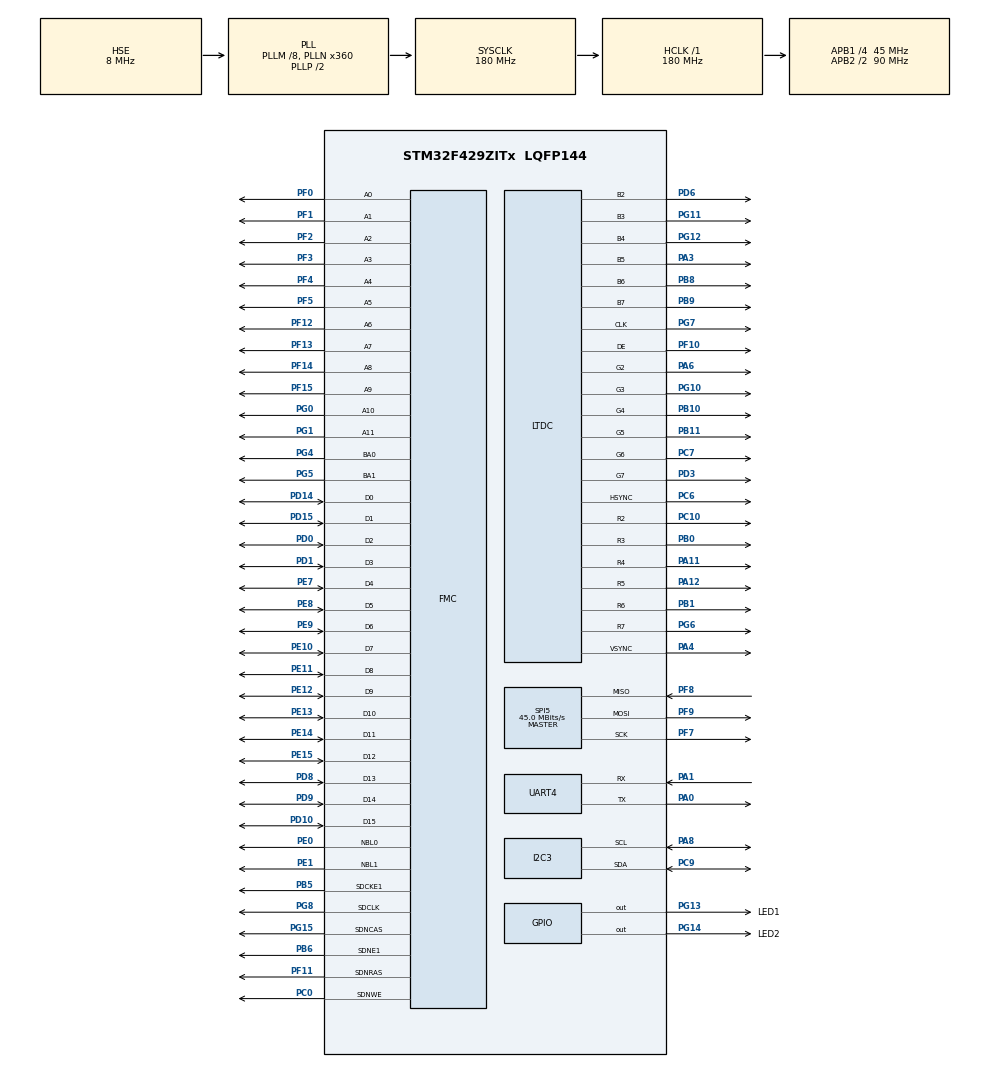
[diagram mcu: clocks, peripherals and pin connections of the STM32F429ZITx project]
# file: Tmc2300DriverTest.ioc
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DMA2D.ColorMode=DMA2D_OUTPUT_RGB565
Dma.Request0=UART4_RX
Dma.Request1=UART4_TX
Dma.UART4_RX.0.Direction=DMA_PERIPH_TO_MEMORY
Dma.UART4_RX.0.FIFOMode=DMA_FIFOMODE_ENABLE
Dma.UART4_RX.0.FIFOThreshold=DMA_FIFO_THRESHOLD_HALFFULL
Dma.UART4_RX.0.Instance=DMA1_Stream2
Dma.UART4_RX.0.MemBurst=DMA_MBURST_SINGLE
Dma.UART4_RX.0.MemDataAlignment=DMA_MDATAALIGN_WORD
Dma.UART4_RX.0.MemInc=DMA_MINC_ENABLE
Dma.UART4_RX.0.Mode=DMA_CIRCULAR
Dma.UART4_RX.0.PeriphBurst=DMA_PBURST_SINGLE
Dma.UART4_RX.0.PeriphDataAlignment=DMA_PDATAALIGN_WORD
Dma.UART4_RX.0.PeriphInc=DMA_PINC_DISABLE
Dma.UART4_RX.0.Priority=DMA_PRIORITY_LOW
Dma.UART4_TX.1.Direction=DMA_MEMORY_TO_PERIPH
Dma.UART4_TX.1.FIFOMode=DMA_FIFOMODE_ENABLE
Dma.UART4_TX.1.FIFOThreshold=DMA_FIFO_THRESHOLD_HALFFULL
Dma.UART4_TX.1.Instance=DMA1_Stream4
Dma.UART4_TX.1.MemBurst=DMA_MBURST_SINGLE
Dma.UART4_TX.1.MemDataAlignment=DMA_MDATAALIGN_WORD
Dma.UART4_TX.1.MemInc=DMA_MINC_ENABLE
Dma.UART4_TX.1.Mode=DMA_NORMAL
Dma.UART4_TX.1.PeriphBurst=DMA_PBURST_SINGLE
Dma.UART4_TX.1.PeriphDataAlignment=DMA_PDATAALIGN_WORD
Dma.UART4_TX.1.PeriphInc=DMA_PINC_DISABLE
Dma.UART4_TX.1.Priority=DMA_PRIORITY_LOW
LTDC.ActiveH=240
LTDC.ActiveW=320
Mcu.Family=STM32F4
Mcu.Name=STM32F429ZITx
Mcu.Package=LQFP144
NVIC.DMA1_Stream2_IRQn=true\:0\:0\:false\:false\:true\:false\:true
NVIC.DMA1_Stream4_IRQn=true\:0\:0\:false\:false\:true\:false\:true
NVIC.PriorityGroup=NVIC_PRIORITYGROUP_4
PA0/WKUP.Mode=Asynchronous
PA0/WKUP.Signal=UART4_TX
PA1.Mode=Asynchronous
PA1.Signal=UART4_RX
PA11.Mode=RGB666
PA11.Signal=LTDC_R4
PA12.Mode=RGB666
PA12.Signal=LTDC_R5
PA3.Mode=RGB666
PA3.Signal=LTDC_B5
PA4.Mode=RGB666
PA4.Signal=LTDC_VSYNC
PA6.Mode=RGB666
PA6.Signal=LTDC_G2
PA8.Mode=I2C
PA8.Signal=I2C3_SCL
PB0.Mode=RGB666
PB0.Signal=LTDC_R3
PB1.Mode=RGB666
PB1.Signal=LTDC_R6
PB10.Mode=RGB666
PB10.Signal=LTDC_G4
PB11.Mode=RGB666
PB11.Signal=LTDC_G5
PB5.Mode=SdramChipSelect2_1
PB5.Signal=FMC_SDCKE1
PB6.Mode=SdramChipSelect2_1
PB6.Signal=FMC_SDNE1
PB8.Mode=RGB666
PB8.Signal=LTDC_B6
PB9.Mode=RGB666
PB9.Signal=LTDC_B7
PC0.Signal=FMC_SDNWE
PC10.Mode=RGB666
PC10.Signal=LTDC_R2
PC14/OSC32_IN.Mode=LSE-External-Oscillator
PC14/OSC32_IN.Signal=RCC_OSC32_IN
PC15/OSC32_OUT.Mode=LSE-External-Oscillator
PC15/OSC32_OUT.Signal=RCC_OSC32_OUT
PC6.Mode=RGB666
PC6.Signal=LTDC_HSYNC
PC7.Mode=RGB666
PC7.Signal=LTDC_G6
PC9.Mode=I2C
PC9.Signal=I2C3_SDA
PD0.Signal=FMC_D2_DA2
PD1.Signal=FMC_D3_DA3
PD10.Signal=FMC_D15_DA15
PD14.Signal=FMC_D0_DA0
PD15.Signal=FMC_D1_DA1
PD3.Mode=RGB666
PD3.Signal=LTDC_G7
PD6.Mode=RGB666
PD6.Signal=LTDC_B2
PD8.Signal=FMC_D13_DA13
PD9.Signal=FMC_D14_DA14
PE0.Signal=FMC_NBL0
PE1.Signal=FMC_NBL1
PE10.Signal=FMC_D7_DA7
PE11.Signal=FMC_D8_DA8
PE12.Signal=FMC_D9_DA9
PE13.Signal=FMC_D10_DA10
PE14.Signal=FMC_D11_DA11
PE15.Signal=FMC_D12_DA12
PE7.Signal=FMC_D4_DA4
PE8.Signal=FMC_D5_DA5
PE9.Signal=FMC_D6_DA6
PF0.Signal=FMC_A0
PF1.Signal=FMC_A1
PF10.Mode=RGB666
PF10.Signal=LTDC_DE
PF11.Signal=FMC_SDNRAS
PF12.Signal=FMC_A6
PF13.Signal=FMC_A7
PF14.Signal=FMC_A8
PF15.Signal=FMC_A9
PF2.Signal=FMC_A2
PF3.Signal=FMC_A3
PF4.Signal=FMC_A4
PF5.Signal=FMC_A5
PF7.Mode=Full_Duplex_Master
PF7.Signal=SPI5_SCK
PF8.Mode=Full_Duplex_Master
PF8.Signal=SPI5_MISO
PF9.Mode=Full_Duplex_Master
PF9.Signal=SPI5_MOSI
PG0.Signal=FMC_A10
PG1.Signal=FMC_A11
PG10.Mode=RGB666
PG10.Signal=LTDC_G3
PG11.Mode=RGB666
PG11.Signal=LTDC_B3
PG12.Mode=RGB666
PG12.Signal=LTDC_B4
PG13.GPIO_Label=LED1
PG13.Signal=GPIO_Output
PG14.GPIO_Label=LED2
PG14.Signal=GPIO_Output
PG15.Signal=FMC_SDNCAS
PG4.Signal=FMC_A14_BA0
PG5.Signal=FMC_A15_BA1
PG6.Mode=RGB666
PG6.Signal=LTDC_R7
PG7.Mode=RGB666
PG7.Signal=LTDC_CLK
PG8.Signal=FMC_SDCLK
PH0/OSC_IN.Mode=HSE-External-Oscillator
PH0/OSC_IN.Signal=RCC_OSC_IN
PH1/OSC_OUT.Mode=HSE-External-Oscillator
PH1/OSC_OUT.Signal=RCC_OSC_OUT
ProjectManager.HeapSize=0x200
ProjectManager.StackSize=0x400
ProjectManager.TargetToolchain=MDK-ARM V5.27
RCC.48MHZClocksFreq_Value=120000000
RCC.AHBFreq_Value=180000000
RCC.APB1CLKDivider=RCC_HCLK_DIV4
RCC.APB1Freq_Value=45000000
RCC.APB1TimFreq_Value=90000000
RCC.APB2CLKDivider=RCC_HCLK_DIV2
RCC.APB2Freq_Value=90000000
RCC.APB2TimFreq_Value=180000000
RCC.CortexFreq_Value=180000000
RCC.HCLKFreq_Value=180000000
RCC.HSE_VALUE=8000000
RCC.HSI_VALUE=16000000
RCC.PLLM=8
RCC.PLLN=360
RCC.PLLQ=3
RCC.PLLSAIN=432
RCC.PLLSourceVirtual=RCC_PLLSOURCE_HSE
RCC.SYSCLKFreq_VALUE=180000000
RCC.SYSCLKSource=RCC_SYSCLKSOURCE_PLLCLK
RCC.VCOOutputFreq_Value=360000000
SH.FMC_A0.0=FMC_A0,12b-sda1
SH.FMC_A1.0=FMC_A1,12b-sda1
SH.FMC_A10.0=FMC_A10,12b-sda1
SH.FMC_A11.0=FMC_A11,12b-sda1
SH.FMC_A14_BA0.0=FMC_BA0,FourSdramBanks1
SH.FMC_A15_BA1.0=FMC_BA1,FourSdramBanks1
SH.FMC_A2.0=FMC_A2,12b-sda1
SH.FMC_A3.0=FMC_A3,12b-sda1
SH.FMC_A4.0=FMC_A4,12b-sda1
SH.FMC_A5.0=FMC_A5,12b-sda1
SH.FMC_A6.0=FMC_A6,12b-sda1
SH.FMC_A7.0=FMC_A7,12b-sda1
SH.FMC_A8.0=FMC_A8,12b-sda1
SH.FMC_A9.0=FMC_A9,12b-sda1
SH.FMC_D0_DA0.0=FMC_D0,sd-16b-d1
SH.FMC_D10_DA10.0=FMC_D10,sd-16b-d1
SH.FMC_D11_DA11.0=FMC_D11,sd-16b-d1
SH.FMC_D12_DA12.0=FMC_D12,sd-16b-d1
SH.FMC_D13_DA13.0=FMC_D13,sd-16b-d1
SH.FMC_D14_DA14.0=FMC_D14,sd-16b-d1
SH.FMC_D15_DA15.0=FMC_D15,sd-16b-d1
SH.FMC_D1_DA1.0=FMC_D1,sd-16b-d1
SH.FMC_D2_DA2.0=FMC_D2,sd-16b-d1
SH.FMC_D3_DA3.0=FMC_D3,sd-16b-d1
SH.FMC_D4_DA4.0=FMC_D4,sd-16b-d1
SH.FMC_D5_DA5.0=FMC_D5,sd-16b-d1
SH.FMC_D6_DA6.0=FMC_D6,sd-16b-d1
SH.FMC_D7_DA7.0=FMC_D7,sd-16b-d1
SH.FMC_D8_DA8.0=FMC_D8,sd-16b-d1
SH.FMC_D9_DA9.0=FMC_D9,sd-16b-d1
SH.FMC_NBL0.0=FMC_NBL0,Sd2ByteEnable1
SH.FMC_NBL1.0=FMC_NBL1,Sd2ByteEnable1
SH.FMC_SDCLK.0=FMC_SDCLK,12b-sda1
SH.FMC_SDNCAS.0=FMC_SDNCAS,12b-sda1
SH.FMC_SDNRAS.0=FMC_SDNRAS,12b-sda1
SH.FMC_SDNWE.0=FMC_SDNWE,12b-sda1
SPI5.BaudRatePrescaler=SPI_BAUDRATEPRESCALER_2
SPI5.CalculateBaudRate=45.0 MBits/s
SPI5.Direction=SPI_DIRECTION_2LINES
SPI5.Mode=SPI_MODE_MASTER
SPI5.VirtualType=VM_MASTER
UART4.VirtualMode=Asynchronous
VP_DMA2D_VS_DMA2D.Mode=DMA2D_Activate
board=STM32F429I-DISC1

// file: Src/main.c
/* USER CODE BEGIN Header */
/**
  ******************************************************************************
  * @file           : main.c
  * @brief          : Main program body
  ******************************************************************************
  * @attention
  *
  * <h2><center>&copy; Copyright (c) 2020 STMicroelectronics.
  * All rights reserved.</center></h2>
  *
  * This software component is licensed by ST under BSD 3-Clause license,
  * the "License"; You may not use this file except in compliance with the
  * License. You may obtain a copy of the License at:
  *                        opensource.org/licenses/BSD-3-Clause
  *
  ******************************************************************************
  */
/* USER CODE END Header */

#include "main.h"

DMA2D_HandleTypeDef hdma2d;

I2C_HandleTypeDef hi2c3;

LTDC_HandleTypeDef hltdc;

SPI_HandleTypeDef hspi5;

UART_HandleTypeDef huart4;
DMA_HandleTypeDef hdma_uart4_rx;
DMA_HandleTypeDef hdma_uart4_tx;

SDRAM_HandleTypeDef hsdram1;

void SystemClock_Config(void);
static void MX_GPIO_Init(void);
static void MX_DMA2D_Init(void);
static void MX_FMC_Init(void);
static void MX_I2C3_Init(void);
static void MX_LTDC_Init(void);
static void MX_SPI5_Init(void);
static void MX_DMA_Init(void);
static void MX_UART4_Init(void);

int main(void)
{

  /* MCU Configuration--------------------------------------------------------*/

  /* Reset of all peripherals, Initializes the Flash interface and the Systick. */
  HAL_Init();

  /* Configure the system clock */
  SystemClock_Config();

  /* Initialize all configured peripherals */
  MX_GPIO_Init();
  MX_DMA2D_Init();
  MX_FMC_Init();
  MX_I2C3_Init();
  MX_LTDC_Init();
  MX_SPI5_Init();
  MX_DMA_Init();
  MX_UART4_Init();
  /* USER CODE BEGIN 2 */

	BSP_LCD_Init();
	BSP_LCD_LayerDefaultInit(LCD_BACKGROUND_LAYER ,LCD_FRAME_BUFFER);
	BSP_LCD_LayerDefaultInit(LCD_FOREGROUND_LAYER ,LCD_FRAME_BUFFER);
	BSP_LCD_SelectLayer(LCD_FOREGROUND_LAYER);
	BSP_LCD_Clear(LCD_COLOR_BLUE);
	BSP_LCD_DisplayOn();

  /* USER CODE END 2 */

  /* Infinite loop */
  while (1)
  {

  }
}

void SystemClock_Config(void)
{
  RCC_OscInitTypeDef RCC_OscInitStruct = {0};
  RCC_ClkInitTypeDef RCC_ClkInitStruct = {0};
  RCC_PeriphCLKInitTypeDef PeriphClkInitStruct = {0};

  /** Configure the main internal regulator output voltage
  */
  __HAL_RCC_PWR_CLK_ENABLE();
  __HAL_PWR_VOLTAGESCALING_CONFIG(PWR_REGULATOR_VOLTAGE_SCALE1);
  /** Initializes the CPU, AHB and APB busses clocks
  */
  RCC_OscInitStruct.OscillatorType = RCC_OSCILLATORTYPE_HSE;
  RCC_OscInitStruct.HSEState = RCC_HSE_ON;
  RCC_OscInitStruct.PLL.PLLState = RCC_PLL_ON;
  RCC_OscInitStruct.PLL.PLLSource = RCC_PLLSOURCE_HSE;
  RCC_OscInitStruct.PLL.PLLM = 8;
  RCC_OscInitStruct.PLL.PLLN = 360;
  RCC_OscInitStruct.PLL.PLLP = RCC_PLLP_DIV2;
  RCC_OscInitStruct.PLL.PLLQ = 3;
  if (HAL_RCC_OscConfig(&RCC_OscInitStruct) != HAL_OK)
  {
    Error_Handler();
  }
  /** Activate the Over-Drive mode
  */
  if (HAL_PWREx_EnableOverDrive() != HAL_OK)
  {
    Error_Handler();
  }
  /** Initializes the CPU, AHB and APB busses clocks
  */
  RCC_ClkInitStruct.ClockType = RCC_CLOCKTYPE_HCLK|RCC_CLOCKTYPE_SYSCLK
                              |RCC_CLOCKTYPE_PCLK1|RCC_CLOCKTYPE_PCLK2;
  RCC_ClkInitStruct.SYSCLKSource = RCC_SYSCLKSOURCE_PLLCLK;
  RCC_ClkInitStruct.AHBCLKDivider = RCC_SYSCLK_DIV1;
  RCC_ClkInitStruct.APB1CLKDivider = RCC_HCLK_DIV4;
  RCC_ClkInitStruct.APB2CLKDivider = RCC_HCLK_DIV2;

  if (HAL_RCC_ClockConfig(&RCC_ClkInitStruct, FLASH_LATENCY_5) != HAL_OK)
  {
    Error_Handler();
  }
  PeriphClkInitStruct.PeriphClockSelection = RCC_PERIPHCLK_LTDC;
  PeriphClkInitStruct.PLLSAI.PLLSAIN = 432;
  PeriphClkInitStruct.PLLSAI.PLLSAIR = 2;
  PeriphClkInitStruct.PLLSAIDivR = RCC_PLLSAIDIVR_2;
  if (HAL_RCCEx_PeriphCLKConfig(&PeriphClkInitStruct) != HAL_OK)
  {
    Error_Handler();
  }
}

static void MX_DMA2D_Init(void)
{

  hdma2d.Instance = DMA2D;
  hdma2d.Init.Mode = DMA2D_M2M;
  hdma2d.Init.ColorMode = DMA2D_OUTPUT_RGB565;
  hdma2d.Init.OutputOffset = 0;
  hdma2d.LayerCfg[1].InputOffset = 0;
  hdma2d.LayerCfg[1].InputColorMode = DMA2D_INPUT_RGB565;
  hdma2d.LayerCfg[1].AlphaMode = DMA2D_NO_MODIF_ALPHA;
  hdma2d.LayerCfg[1].InputAlpha = 0;
  if (HAL_DMA2D_Init(&hdma2d) != HAL_OK)
  {
    Error_Handler();
  }
  if (HAL_DMA2D_ConfigLayer(&hdma2d, 1) != HAL_OK)
  {
    Error_Handler();
  }

}

static void MX_I2C3_Init(void)
{

  hi2c3.Instance = I2C3;
  hi2c3.Init.ClockSpeed = 100000;
  hi2c3.Init.DutyCycle = I2C_DUTYCYCLE_2;
  hi2c3.Init.OwnAddress1 = 0;
  hi2c3.Init.AddressingMode = I2C_ADDRESSINGMODE_7BIT;
  hi2c3.Init.DualAddressMode = I2C_DUALADDRESS_DISABLE;
  hi2c3.Init.OwnAddress2 = 0;
  hi2c3.Init.GeneralCallMode = I2C_GENERALCALL_DISABLE;
  hi2c3.Init.NoStretchMode = I2C_NOSTRETCH_DISABLE;
  if (HAL_I2C_Init(&hi2c3) != HAL_OK)
  {
    Error_Handler();
  }
  /** Configure Analogue filter
  */
  if (HAL_I2CEx_ConfigAnalogFilter(&hi2c3, I2C_ANALOGFILTER_ENABLE) != HAL_OK)
  {
    Error_Handler();
  }
  /** Configure Digital filter
  */
  if (HAL_I2CEx_ConfigDigitalFilter(&hi2c3, 0) != HAL_OK)
  {
    Error_Handler();
  }

}

static void MX_LTDC_Init(void)
{

  LTDC_LayerCfgTypeDef pLayerCfg = {0};
  LTDC_LayerCfgTypeDef pLayerCfg1 = {0};

  hltdc.Instance = LTDC;
  hltdc.Init.HSPolarity = LTDC_HSPOLARITY_AL;
  hltdc.Init.VSPolarity = LTDC_VSPOLARITY_AL;
  hltdc.Init.DEPolarity = LTDC_DEPOLARITY_AL;
  hltdc.Init.PCPolarity = LTDC_PCPOLARITY_IPC;
  hltdc.Init.HorizontalSync = 7;
  hltdc.Init.VerticalSync = 3;
  hltdc.Init.AccumulatedHBP = 14;
  hltdc.Init.AccumulatedVBP = 5;
  hltdc.Init.AccumulatedActiveW = 334;
  hltdc.Init.AccumulatedActiveH = 245;
  hltdc.Init.TotalWidth = 340;
  hltdc.Init.TotalHeigh = 247;
  hltdc.Init.Backcolor.Blue = 0;
  hltdc.Init.Backcolor.Green = 0;
  hltdc.Init.Backcolor.Red = 0;
  if (HAL_LTDC_Init(&hltdc) != HAL_OK)
  {
    Error_Handler();
  }
  pLayerCfg.WindowX0 = 0;
  pLayerCfg.WindowX1 = 0;
  pLayerCfg.WindowY0 = 0;
  pLayerCfg.WindowY1 = 0;
  pLayerCfg.PixelFormat = LTDC_PIXEL_FORMAT_ARGB8888;
  pLayerCfg.Alpha = 0;
  pLayerCfg.Alpha0 = 0;
  pLayerCfg.BlendingFactor1 = LTDC_BLENDING_FACTOR1_CA;
  pLayerCfg.BlendingFactor2 = LTDC_BLENDING_FACTOR2_CA;
  pLayerCfg.FBStartAdress = 0;
  pLayerCfg.ImageWidth = 0;
  pLayerCfg.ImageHeight = 0;
  pLayerCfg.Backcolor.Blue = 0;
  pLayerCfg.Backcolor.Green = 0;
  pLayerCfg.Backcolor.Red = 0;
  if (HAL_LTDC_ConfigLayer(&hltdc, &pLayerCfg, 0) != HAL_OK)
  {
    Error_Handler();
  }
  pLayerCfg1.WindowX0 = 0;
  pLayerCfg1.WindowX1 = 0;
  pLayerCfg1.WindowY0 = 0;
  pLayerCfg1.WindowY1 = 0;
  pLayerCfg1.PixelFormat = LTDC_PIXEL_FORMAT_ARGB8888;
  pLayerCfg1.Alpha = 0;
  pLayerCfg1.Alpha0 = 0;
  pLayerCfg1.BlendingFactor1 = LTDC_BLENDING_FACTOR1_CA;
  pLayerCfg1.BlendingFactor2 = LTDC_BLENDING_FACTOR2_CA;
  pLayerCfg1.FBStartAdress = 0;
  pLayerCfg1.ImageWidth = 0;
  pLayerCfg1.ImageHeight = 0;
  pLayerCfg1.Backcolor.Blue = 0;
  pLayerCfg1.Backcolor.Green = 0;
  pLayerCfg1.Backcolor.Red = 0;
  if (HAL_LTDC_ConfigLayer(&hltdc, &pLayerCfg1, 1) != HAL_OK)
  {
    Error_Handler();
  }

}

static void MX_SPI5_Init(void)
{

  /* SPI5 parameter configuration*/
  hspi5.Instance = SPI5;
  hspi5.Init.Mode = SPI_MODE_MASTER;
  hspi5.Init.Direction = SPI_DIRECTION_2LINES;
  hspi5.Init.DataSize = SPI_DATASIZE_8BIT;
  hspi5.Init.CLKPolarity = SPI_POLARITY_LOW;
  hspi5.Init.CLKPhase = SPI_PHASE_1EDGE;
  hspi5.Init.NSS = SPI_NSS_SOFT;
  hspi5.Init.BaudRatePrescaler = SPI_BAUDRATEPRESCALER_2;
  hspi5.Init.FirstBit = SPI_FIRSTBIT_MSB;
  hspi5.Init.TIMode = SPI_TIMODE_DISABLE;
  hspi5.Init.CRCCalculation = SPI_CRCCALCULATION_DISABLE;
  hspi5.Init.CRCPolynomial = 10;
  if (HAL_SPI_Init(&hspi5) != HAL_OK)
  {
    Error_Handler();
  }

}

static void MX_UART4_Init(void)
{

  huart4.Instance = UART4;
  huart4.Init.BaudRate = 115200;
  huart4.Init.WordLength = UART_WORDLENGTH_8B;
  huart4.Init.StopBits = UART_STOPBITS_1;
  huart4.Init.Parity = UART_PARITY_NONE;
  huart4.Init.Mode = UART_MODE_TX_RX;
  huart4.Init.HwFlowCtl = UART_HWCONTROL_NONE;
  huart4.Init.OverSampling = UART_OVERSAMPLING_16;
  if (HAL_UART_Init(&huart4) != HAL_OK)
  {
    Error_Handler();
  }

}

static void MX_DMA_Init(void)
{

  /* DMA controller clock enable */
  __HAL_RCC_DMA1_CLK_ENABLE();

  /* DMA interrupt init */
  /* DMA1_Stream2_IRQn interrupt configuration */
  HAL_NVIC_SetPriority(DMA1_Stream2_IRQn, 0, 0);
  HAL_NVIC_EnableIRQ(DMA1_Stream2_IRQn);
  /* DMA1_Stream4_IRQn interrupt configuration */
  HAL_NVIC_SetPriority(DMA1_Stream4_IRQn, 0, 0);
  HAL_NVIC_EnableIRQ(DMA1_Stream4_IRQn);

}

/* FMC initialization function */
static void MX_FMC_Init(void)
{

  FMC_SDRAM_TimingTypeDef SdramTiming = {0};

  /** Perform the SDRAM1 memory initialization sequence
  */
  hsdram1.Instance = FMC_SDRAM_DEVICE;
  /* hsdram1.Init */
  hsdram1.Init.SDBank = FMC_SDRAM_BANK2;
  hsdram1.Init.ColumnBitsNumber = FMC_SDRAM_COLUMN_BITS_NUM_8;
  hsdram1.Init.RowBitsNumber = FMC_SDRAM_ROW_BITS_NUM_12;
  hsdram1.Init.MemoryDataWidth = FMC_SDRAM_MEM_BUS_WIDTH_16;
  hsdram1.Init.InternalBankNumber = FMC_SDRAM_INTERN_BANKS_NUM_4;
  hsdram1.Init.CASLatency = FMC_SDRAM_CAS_LATENCY_1;
  hsdram1.Init.WriteProtection = FMC_SDRAM_WRITE_PROTECTION_DISABLE;
  hsdram1.Init.SDClockPeriod = FMC_SDRAM_CLOCK_DISABLE;
  hsdram1.Init.ReadBurst = FMC_SDRAM_RBURST_DISABLE;
  hsdram1.Init.ReadPipeDelay = FMC_SDRAM_RPIPE_DELAY_0;
  /* SdramTiming */
  SdramTiming.LoadToActiveDelay = 16;
  SdramTiming.ExitSelfRefreshDelay = 16;
  SdramTiming.SelfRefreshTime = 16;
  SdramTiming.RowCycleDelay = 16;
  SdramTiming.WriteRecoveryTime = 16;
  SdramTiming.RPDelay = 16;
  SdramTiming.RCDDelay = 16;

  if (HAL_SDRAM_Init(&hsdram1, &SdramTiming) != HAL_OK)
  {
    Error_Handler( );
  }

}

static void MX_GPIO_Init(void)
{
  GPIO_InitTypeDef GPIO_InitStruct = {0};

  /* GPIO Ports Clock Enable */
  __HAL_RCC_GPIOC_CLK_ENABLE();
  __HAL_RCC_GPIOF_CLK_ENABLE();
  __HAL_RCC_GPIOH_CLK_ENABLE();
  __HAL_RCC_GPIOA_CLK_ENABLE();
  __HAL_RCC_GPIOB_CLK_ENABLE();
  __HAL_RCC_GPIOG_CLK_ENABLE();
  __HAL_RCC_GPIOE_CLK_ENABLE();
  __HAL_RCC_GPIOD_CLK_ENABLE();

  /*Configure GPIO pin Output Level */
  HAL_GPIO_WritePin(GPIOG, LED1_Pin|LED2_Pin, GPIO_PIN_RESET);

  /*Configure GPIO pins : LED1_Pin LED2_Pin */
  GPIO_InitStruct.Pin = LED1_Pin|LED2_Pin;
  GPIO_InitStruct.Mode = GPIO_MODE_OUTPUT_PP;
  GPIO_InitStruct.Pull = GPIO_NOPULL;
  GPIO_InitStruct.Speed = GPIO_SPEED_FREQ_LOW;
  HAL_GPIO_Init(GPIOG, &GPIO_InitStruct);

}

void Error_Handler(void)
{
}

/************************ (C) COPYRIGHT STMicroelectronics *****END OF FILE****/
